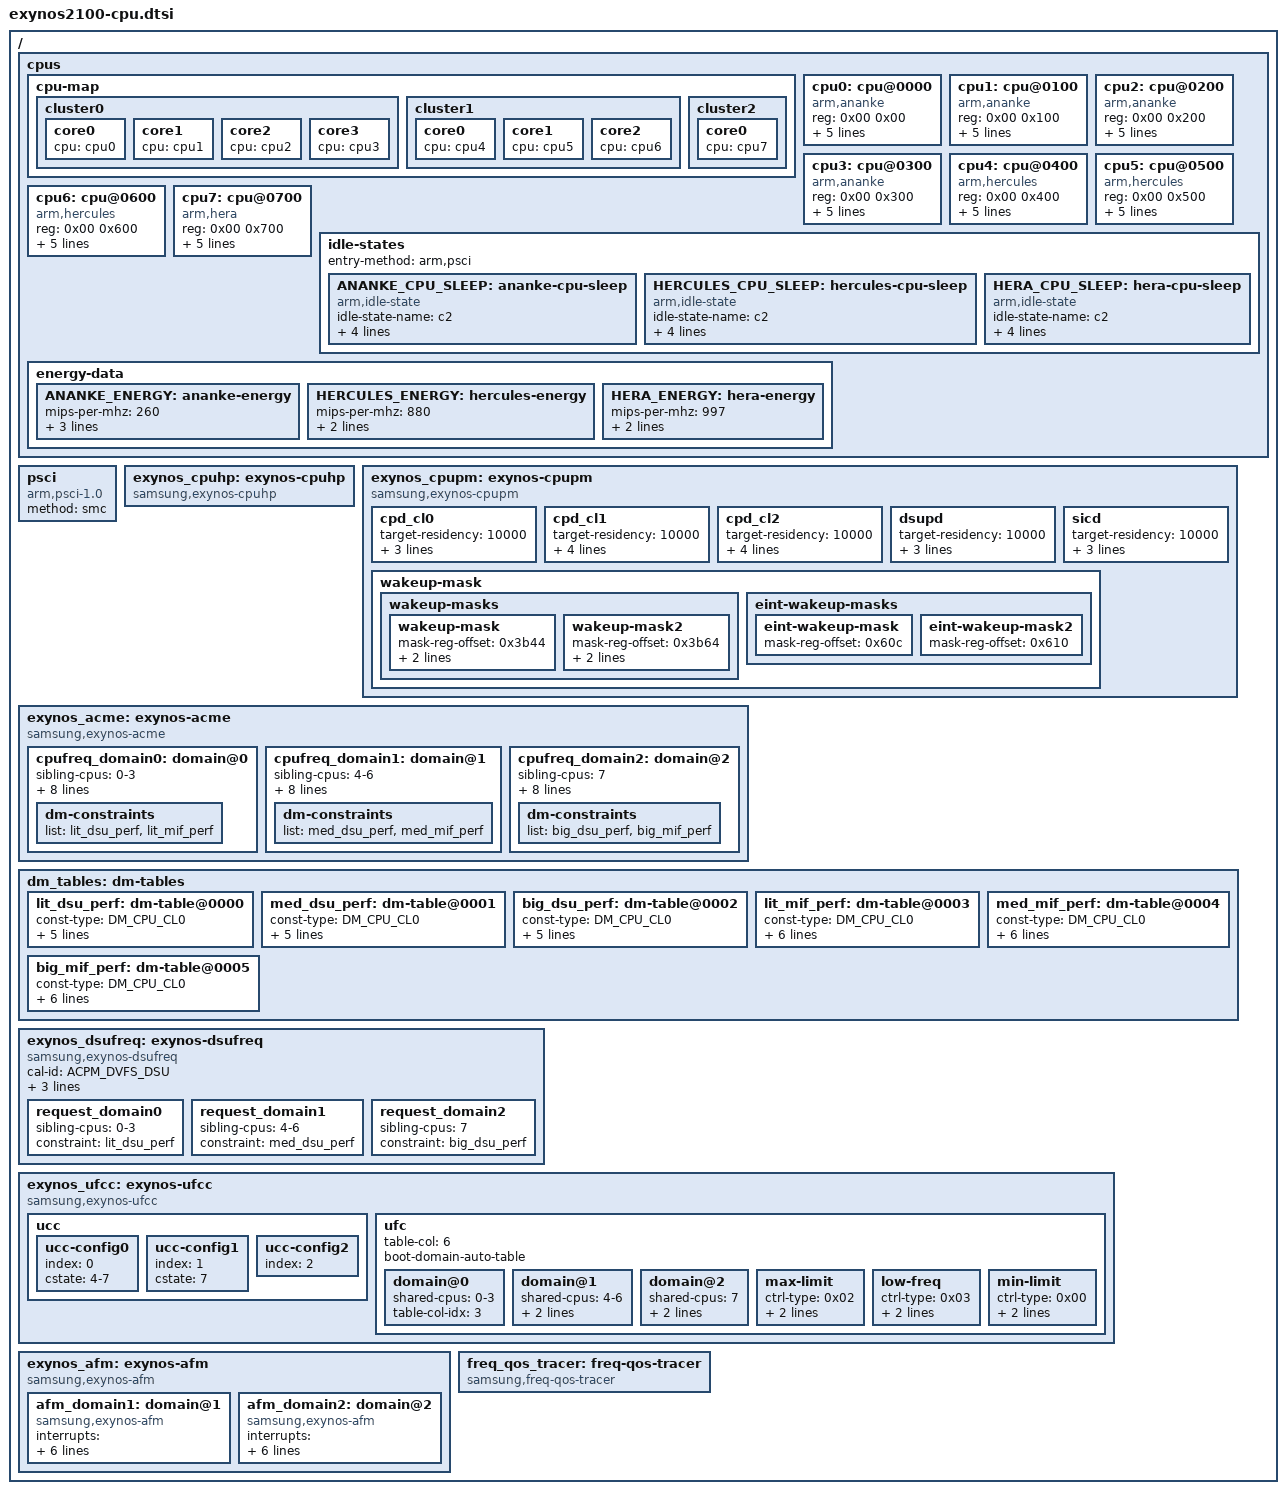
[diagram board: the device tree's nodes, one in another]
// SPDX-License-Identifier: GPL-2.0-only
/*
 * Exynos2100 SoC CPU device tree source
 *
 * Copyright (c) 2026 Samsung Electronics Co., Ltd.
 *             http://www.samsung.com
 *
 *
 */

#include <dt-bindings/soc/samsung/cpupm.h>

/ {
	cpus: cpus {
		#address-cells = <2>;
		#size-cells = <0>;

		cpu-map {
			cluster0 {
				core0 { cpu = <&cpu0>; };
				core1 { cpu = <&cpu1>; };
				core2 { cpu = <&cpu2>; };
				core3 { cpu = <&cpu3>; };
			};

			cluster1 {
				core0 { cpu = <&cpu4>; };
				core1 { cpu = <&cpu5>; };
				core2 { cpu = <&cpu6>;};
			};

			cluster2 {
				core0 { cpu = <&cpu7>; };
			};
		};

		cpu0: cpu@0000 {
			device_type = "cpu";
			compatible = "arm,ananke", "arm,armv8";
			reg = <0x00 0x00>;
			capacity-dmips-mhz = <260>;
			dynamic-power-coefficient = <89>;
			enable-method = "psci";
			cpu-idle-states = <&ANANKE_CPU_SLEEP>;
			sched-energy-data = <&ANANKE_ENERGY>;
		};

		cpu1: cpu@0100 {
			device_type = "cpu";
			compatible = "arm,ananke", "arm,armv8";
			reg = <0x00 0x100>;
			capacity-dmips-mhz = <260>;
			dynamic-power-coefficient = <89>;
			enable-method = "psci";
			cpu-idle-states = <&ANANKE_CPU_SLEEP>;
			sched-energy-data = <&ANANKE_ENERGY>;
		};

		cpu2: cpu@0200 {
			device_type = "cpu";
			compatible = "arm,ananke", "arm,armv8";
			reg = <0x00 0x200>;
			capacity-dmips-mhz = <260>;
			dynamic-power-coefficient = <89>;
			enable-method = "psci";
			cpu-idle-states = <&ANANKE_CPU_SLEEP>;
			sched-energy-data = <&ANANKE_ENERGY>;
		};

		cpu3: cpu@0300 {
			device_type = "cpu";
			compatible = "arm,ananke", "arm,armv8";
			reg = <0x00 0x300>;
			capacity-dmips-mhz = <260>;
			dynamic-power-coefficient = <89>;
			enable-method = "psci";
			cpu-idle-states = <&ANANKE_CPU_SLEEP>;
			sched-energy-data = <&ANANKE_ENERGY>;
		};

		cpu4: cpu@0400 {
			device_type = "cpu";
			compatible = "arm,hercules", "arm,armv8";
			reg = <0x00 0x400>;
			capacity-dmips-mhz = <880>;
			dynamic-power-coefficient = <513>;
			enable-method = "psci";
			cpu-idle-states = <&HERCULES_CPU_SLEEP>;
			sched-energy-data = <&HERCULES_ENERGY>;
		};

		cpu5: cpu@0500 {
			device_type = "cpu";
			compatible = "arm,hercules", "arm,armv8";
			reg = <0x00 0x500>;
			capacity-dmips-mhz = <880>;
			dynamic-power-coefficient = <513>;
			enable-method = "psci";
			cpu-idle-states = <&HERCULES_CPU_SLEEP>;
			sched-energy-data = <&HERCULES_ENERGY>;
		};

		cpu6: cpu@0600 {
			device_type = "cpu";
			compatible = "arm,hercules", "arm,armv8";
			reg = <0x00 0x600>;
			capacity-dmips-mhz = <880>;
			dynamic-power-coefficient = <513>;
			enable-method = "psci";
			cpu-idle-states = <&HERCULES_CPU_SLEEP>;
			sched-energy-data = <&HERCULES_ENERGY>;
		};

		cpu7: cpu@0700 {
			device_type = "cpu";
			compatible = "arm,hera", "arm,armv8";
			reg = <0x00 0x700>;
			capacity-dmips-mhz = <997>;
			dynamic-power-coefficient = <757>;
			enable-method = "psci";
			cpu-idle-states = <&HERA_CPU_SLEEP>;
			sched-energy-data = <&HERA_ENERGY>;
		};

		idle-states {
			entry-method = "arm,psci";
			ANANKE_CPU_SLEEP: ananke-cpu-sleep {
				idle-state-name = "c2";
				compatible = "arm,idle-state";
				arm,psci-suspend-param = <0x10000>;
				entry-latency-us = <70>;
				exit-latency-us = <160>;
				min-residency-us = <2000>;
				status = "okay";
			};
			HERCULES_CPU_SLEEP: hercules-cpu-sleep {
				idle-state-name = "c2";
				compatible = "arm,idle-state";
				arm,psci-suspend-param = <0x10000>;
				entry-latency-us = <150>;
				exit-latency-us = <190>;
				min-residency-us = <2500>;
				status = "okay";
			};
			HERA_CPU_SLEEP: hera-cpu-sleep {
				idle-state-name = "c2";
				compatible = "arm,idle-state";
				arm,psci-suspend-param = <0x10000>;
				entry-latency-us = <235>;
				exit-latency-us = <220>;
				min-residency-us = <3500>;
				status = "okay";
			};
		};

		energy-data {
			ANANKE_ENERGY: ananke-energy {
				mips-per-mhz = <260>;
				power-coefficient = <89>;
				static-power-coefficient = <87>;
				static-power-coefficient-2nd = <20>;
			};
			HERCULES_ENERGY: hercules-energy {
				mips-per-mhz = <880>;
				power-coefficient = <513>;
				static-power-coefficient = <253>;
			};
			HERA_ENERGY: hera-energy {
				mips-per-mhz = <997>;
				power-coefficient = <757>;
				static-power-coefficient = <313>;
			};
		};
	};

	psci: psci {
		compatible = "arm,psci-1.0";
		method = "smc";
	};

	exynos_cpuhp: exynos-cpuhp {
		compatible = "samsung,exynos-cpuhp";
		status = "okay";
	};

	exynos_cpupm: exynos-cpupm {
		compatible = "samsung,exynos-cpupm";
		status = "okay";

		cpd_cl0 {
			device_type = "cpupm";
			target-residency = <10000>;
			type = <POWERMODE_TYPE_CLUSTER>;
			cal-id = <NONE>;
			siblings = "0-3";
		};

		cpd_cl1 {
			device_type = "cpupm";
			target-residency = <10000>;
			type = <POWERMODE_TYPE_CLUSTER>;
			cal-id = <1>;
			siblings = "4-6";
			entry-allowed = "4-6";
		};

		cpd_cl2 {
			device_type = "cpupm";
			target-residency = <10000>;
			type = <POWERMODE_TYPE_CLUSTER>;
			cal-id = <2>;
			siblings = "7";
			entry-allowed = "7";
		};

		dsupd {
			device_type = "cpupm";
			target-residency = <10000>;
			type = <POWERMODE_TYPE_DSU>;
			siblings = "0-7";
			entry-allowed = "0-7";
		};

		sicd {
			device_type = "cpupm";
			target-residency = <10000>;
			type = <POWERMODE_TYPE_SYSTEM>;
			siblings = "0-7";
			entry-allowed = "0-7";
		};

		wakeup-mask {
			wakeup-masks {
				wakeup-mask {
					mask-reg-offset = <0x3b44>;
					stat-reg-offset = <0x3b50>;
					mask = <0xff000000>;
				};
				wakeup-mask2 {
					mask-reg-offset = <0x3b64>;
					stat-reg-offset = <0x3b54>;
					mask = <0x00>;
				};
			};

			eint-wakeup-masks {
				eint-wakeup-mask {
					mask-reg-offset = <0x60c>;
				};
				eint-wakeup-mask2 {
					mask-reg-offset = <0x610>;
				};
			};
		};
	};

	exynos_acme: exynos-acme {
		compatible = "samsung,exynos-acme";
		status = "okay";

		cpufreq_domain0: domain@0 {
			sibling-cpus = "0-3";
			cal-id = <ACPM_DVFS_CPUCL0>;
			dm-type = <DM_CPU_CL0>;
			max-freq = <2210000>;
			min-freq = <400000>;
			#cooling-cells = <2>;
			ect-coeff-index = <2>;
			tz-cooling-name = "LITTLE";
			freq-table = <
				177000 266000
				400000 533000
				650000 754000
				858000 962000
				1066000 1170000
				1274000 1378000
				1482000 1586000
				1690000 1794000
				1898000 2002000
				2106000 2210000
				2314000 2392000>;

			dm-constraints {
				list = <&lit_dsu_perf>, <&lit_mif_perf>;
			};
		};

		cpufreq_domain1: domain@1 {
			sibling-cpus = "4-6";
			cal-id = <ACPM_DVFS_CPUCL1>;
			dm-type = <DM_CPU_CL1>;
			max-freq = <2808000>;
			min-freq = <533000>;
			#cooling-cells = <2>;
			ect-coeff-index = <1>;
			tz-cooling-name = "MID";
			freq-table = <
				177000 266000
				400000 533000
				624000 728000
				832000 936000
				1040000 1144000
				1248000 1352000
				1456000 1560000
				1664000 1768000
				1872000 1976000
				2080000 2184000
				2288000 2392000
				2496000 2600000
				2704000 2808000
				2912000 2990000>;

			dm-constraints {
				list = <&med_dsu_perf>, <&med_mif_perf>;
			};
		};

		cpufreq_domain2: domain@2 {
			sibling-cpus = "7";
			cal-id = <ACPM_DVFS_CPUCL2>;
			dm-type = <DM_CPU_CL2>;
			max-freq = <2912000>;
			min-freq = <533000>;
			#cooling-cells = <2>;
			ect-coeff-index = <0>;
			tz-cooling-name = "BIG";
			freq-table = <
				177000 266000
				400000 533000
				624000 728000
				832000 936000
				1040000 1144000
				1248000 1352000
				1456000 1560000
				1664000 1768000
				1872000 1976000
				2080000 2184000
				2288000 2392000
				2496000 2600000
				2704000 2808000
				2912000 2990000>;

			dm-constraints {
				list = <&big_dsu_perf>, <&big_mif_perf>;
			};
		};
	};

	dm_tables: dm-tables {
		lit_dsu_perf: dm-table@0000 {
			const-type = <DM_CPU_CL0>;
			dm-slave = <DM_DSU>;
			master-cal-id = <ACPM_DVFS_CPUCL0>;
			slave-cal-id = <ACPM_DVFS_DSU>;
			table = <
				177000 177000
				266000 177000
				400000 266000
				533000 266000
				650000 400000
				754000 533000
				858000 533000
				962000 650000
				1066000 650000
				1170000 754000
				1274000 858000
				1378000 962000
				1482000 962000
				1586000 1066000
				1690000 1170000
				1794000 1170000
				1898000 1274000
				2002000 1378000
				2106000 1378000
				2210000 1482000
				2314000 1586000
				2392000 1690000>;
		};

		med_dsu_perf: dm-table@0001 {
			const-type = <DM_CPU_CL0>;
			dm-slave = <DM_DSU>;
			master-cal-id = <ACPM_DVFS_CPUCL1>;
			slave-cal-id = <ACPM_DVFS_DSU>;
			table = <
				177000 177000
				266000 177000
				400000 266000
				533000 266000
				624000 400000
				728000 400000
				832000 533000
				936000 650000
				1040000 650000
				1144000 754000
				1248000 858000
				1352000 858000
				1456000 962000
				1560000 1066000
				1664000 1170000
				1768000 1170000
				1872000 1274000
				1976000 1378000
				2080000 1378000
				2184000 1482000
				2288000 1586000
				2392000 1586000
				2496000 1690000
				2600000 1794000
				2704000 1794000
				2808000 1898000
				2912000 2002000
				2990000 2002000>;
		};

		big_dsu_perf: dm-table@0002 {
			const-type = <DM_CPU_CL0>;
			dm-slave = <DM_DSU>;
			master-cal-id = <ACPM_DVFS_CPUCL2>;
			slave-cal-id = <ACPM_DVFS_DSU>;
			table = <
				177000 177000
				266000 177000
				400000 266000
				533000 266000
				624000 400000
				728000 400000
				832000 533000
				936000 650000
				1040000 650000
				1144000 754000
				1248000 858000
				1352000 858000
				1456000 962000
				1560000 1066000
				1664000 1170000
				1768000 1170000
				1872000 1274000
				1976000 1378000
				2080000 1378000
				2184000 1482000
				2288000 1586000
				2392000 1586000
				2496000 1690000
				2600000 1794000
				2704000 1794000
				2808000 1898000
				2912000 1898000
				2990000 2002000>;
		};

		lit_mif_perf: dm-table@0003 {
			const-type = <DM_CPU_CL0>;
			dm-slave = <DM_MIF>;
			master-cal-id = <ACPM_DVFS_CPUCL0>;
			slave-cal-id = <ACPM_DVFS_MIF>;
			dynamic-disable;
			table = <
				177000 0
				266000 0
				400000 0
				533000 0
				650000 0
				754000 0
				858000 0
				962000 0
				1066000 0
				1170000 0
				1274000 0
				1378000 0
				1482000 0
				1586000 0
				1690000 0
				1794000 0
				1898000 0
				2002000 0
				2106000 0
				2210000 0
				2314000 0
				2392000 0>;
		};

		med_mif_perf: dm-table@0004 {
			const-type = <DM_CPU_CL0>;
			dm-slave = <DM_MIF>;
			master-cal-id = <ACPM_DVFS_CPUCL1>;
			slave-cal-id = <ACPM_DVFS_MIF>;
			dynamic-disable;
			table = <
				177000 0
				266000 0
				400000 0
				533000 0
				624000 0
				728000 0
				832000 0
				936000 0
				1040000 0
				1144000 0
				1248000 0
				1352000 0
				1456000 0
				1560000 0
				1664000 0
				1768000 0
				1872000 0
				1976000 0
				2080000 2288000
				2184000 2288000
				2288000 2535000
				2392000 2535000
				2496000 2730000
				2600000 2730000
				2704000 3172000
				2808000 3172000
				2912000 3172000
				2990000 3172000>;
		};

		big_mif_perf: dm-table@0005 {
			const-type = <DM_CPU_CL0>;
			dm-slave = <DM_MIF>;
			master-cal-id = <ACPM_DVFS_CPUCL2>;
			slave-cal-id = <ACPM_DVFS_MIF>;
			dynamic-disable;
			table = <
				177000 0
				266000 0
				400000 0
				533000 0
				624000 0
				728000 0
				832000 0
				936000 0
				1040000 0
				1144000 0
				1248000 0
				1352000 0
				1456000 0
				1560000 0
				1664000 0
				1768000 0
				1872000 0
				1976000 0
				2080000 2288000
				2184000 2288000
				2288000 2535000
				2392000 2535000
				2496000 2730000
				2600000 2730000
				2704000 3172000
				2808000 3172000
				2912000 3172000
				2990000 3172000>;
		};
	};

	exynos_dsufreq: exynos-dsufreq {
		compatible = "samsung,exynos-dsufreq";
		status = "okay";
		cal-id = <ACPM_DVFS_DSU>;
		dm-type = <DM_DSU>;
		dss-type = <ESS_FLAG_DSU>;
		init-with-dt = <1>;

		request_domain0 {
			sibling-cpus = "0-3";
			constraint = <&lit_dsu_perf>;
		};

		request_domain1 {
			sibling-cpus = "4-6";
			constraint = <&med_dsu_perf>;
		};

		request_domain2 {
			sibling-cpus = "7";
			constraint = <&big_dsu_perf>;
		};
	};

	exynos_ufcc: exynos-ufcc {
		compatible = "samsung,exynos-ufcc";
		status = "okay";

		ucc {
			ucc-config0 {
				index = <0>;
				cstate = "4-7";
			};
			ucc-config1 {
				index = <1>;
				cstate = "7";
			};
			ucc-config2 {
				index = <2>;
			};
		};

		ufc {
			table-col = <6>;
			boot-domain-auto-table;
			domain@0 {
				device_type = "ufc-domain";
				shared-cpus = "0-3";
				table-col-idx = <3>;
			};
			domain@1 {
				device_type = "ufc-domain";
				shared-cpus = "4-6";
				table-col-idx = <2>;
				allow-disable-cpus;
			};
			domain@2 {
				device_type = "ufc-domain";
				shared-cpus = "7";
				table-col-idx = <1>;
				allow-disable-cpus;
			};

			max-limit {
				device_type = "ufc-table";
				ctrl-type = <0x02>;
				table = <
				/* VFREQ     BIG(P)   MED      LIT  EMS STRICT */
				2912000  2912000  2808000  2210000  0    0
				2808000  2808000  2808000  1898000  0    0
				2704000  2704000  2704000  1898000  0    0
				2600000  2600000  2600000  1898000  0    0
				2496000  2496000  2496000  1898000  0    0
				2392000  2392000  2392000  1794000  0    0
				2288000  2288000  2288000  1794000  0    0
				2184000  2184000  2184000  1794000  0    0
				2080000  2080000  2080000  1794000  0    0
				1976000  1976000  1976000  1690000  0    0
				1872000  1872000  1872000  1690000  0    0
				1768000  1768000  1768000  1690000  0    0
				1664000  1664000  1664000  1690000  0    0
				1560000  1560000  1560000  1690000  0    0
				1456000  1456000  1456000  1586000  0    0
				1352000  1352000  1352000  1586000  0    0
				1248000  1248000  1248000  1586000  0    0
				1144000  1144000  1144000  1586000  0    0
				1040000  1040000  1040000  1482000  0    0
				936000   936000   936000  1482000  0    0
				832000   832000   832000  1378000  0    0
				728000   728000   728000  1378000  0    0
				624000   624000   624000  1378000  0    0
				533000   533000   533000  1378000  0    0
				>;
			};

			low-freq {
				device_type = "ufc-table";
				ctrl-type = <0x03>;
				table = <
				/* VFREQ     BIG(P)   MED      LIT  EMS STRICT */
				2912000  1976000  1872000  1378000	0	0
				2808000  1872000  1872000  1378000	0	0
				2704000  1768000  1768000  1378000	0	0
				2600000  1664000  1664000  1274000	0	0
				2496000  1664000  1560000  1274000	0	0
				2392000  1560000  1456000  1274000	0	0
				2288000  1456000  1456000   754000	0	0
				2184000  1456000  1352000   754000	0	0
				2080000  1352000  1352000   754000	0	0
				1976000  1248000  1248000   754000	0	0
				1872000  1248000  1144000   754000	0	0
				1768000  1144000  1144000   754000	0	0
				1664000  1040000  1040000   754000	0	0
				1560000  1040000  1040000   754000	0	0
				1456000   936000   936000   754000	0	0
				1352000   832000   832000   754000	0	0
				1248000   832000   832000   754000	0	0
				1144000   728000   728000   754000	0	0
				1040000   728000   624000   533000	0	0
				936000    624000   624000   533000	0	0
				832000    533000   533000   533000	0	0
				728000    533000   533000   533000	0	0
				624000    533000   533000   533000	0	0
				533000    533000   533000   400000	0	0
				>;
			};

			min-limit {
				device_type = "ufc-table";
				ctrl-type = <0x00>;
				table = <
				/* VFREQ     BIG(P)   MED      LIT  EMS STRICT */
				2912000  2912000  2808000  2210000  2    1
				2808000  2808000  2808000  2210000  2    1
				2704000  2704000  2704000  2210000  2    1
				2600000  2600000  2600000  2210000  2    1
				2496000  2496000  2496000  2210000  2    1
				2392000  2392000  2392000  2210000  2    1
				2288000  2288000  2288000  1170000  1    1
				2184000  2184000  2184000  1170000  1    1
				2080000  2080000  2080000  1170000  1    1
				1976000  1976000  1976000  1170000  1    1
				1872000  1872000  1872000  1170000  1    1
				1768000  1768000  1768000  1170000  1    1
				1664000  1664000  1664000  1170000  1    1
				1560000  1560000  1560000  1170000  1    1
				1456000  1456000  1456000  1170000  1    1
				1352000  1352000  1352000  1170000  1    1
				1248000  1248000  1248000  1170000  1    1
				1144000  1144000  1144000  1170000  1    1
				1040000  1040000  1040000   858000  1    1
				936000   936000   936000   858000  1    0
				832000   832000   832000   858000  1    0
				728000   728000   728000   858000  1    0
				624000   624000   624000   858000  1    0
				533000   533000   533000   858000  1    0
				>;
			};
		};
	};

	exynos_afm: exynos-afm {
		compatible = "samsung,exynos-afm";
		status = "okay";

		afm_domain1: domain@1 {
			device_type = "afm-domain";
			compatible = "samsung,exynos-afm";
			interrupts = <GIC_SPI INTREQ__OCP_REATOR_CPUCL0_1 IRQ_TYPE_LEVEL_HIGH>;
			sibling-cpus = "4-6";
			cluster = <1>;
			down-step = <1>;
			max-freq-wo-afm = <2080000>;
			release-duration = <15>;
		};

		afm_domain2: domain@2 {
			device_type = "afm-domain";
			compatible = "samsung,exynos-afm";
			interrupts = <GIC_SPI INTREQ__OCP_REATOR_CPUCL0_2 IRQ_TYPE_LEVEL_HIGH>;
			sibling-cpus = "7";
			cluster = <2>;
			down-step = <1>;
			max-freq-wo-afm = <2080000>;
			release-duration = <15>;
		};
	};

	freq_qos_tracer: freq-qos-tracer {
		compatible = "samsung,freq-qos-tracer";
		status = "okay";
	};
};
